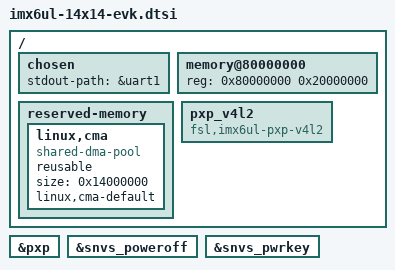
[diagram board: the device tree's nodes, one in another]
// SPDX-License-Identifier: GPL-2.0
//
// Copyright (C) 2015 Freescale Semiconductor, Inc.

#include <dt-bindings/media/video-interfaces.h>

/ {
	chosen {
		stdout-path = &uart1;
	};

	memory@80000000 {
		device_type = "memory";
		reg = <0x80000000 0x20000000>;
	};

	reserved-memory {
		#address-cells = <1>;
		#size-cells = <1>;
		ranges;

		linux,cma {
			compatible = "shared-dma-pool";
			reusable;
			size = <0x14000000>;
			linux,cma-default;
		};
	};

	pxp_v4l2 {
		compatible = "fsl,imx6ul-pxp-v4l2", "fsl,imx6sx-pxp-v4l2", "fsl,imx6sl-pxp-v4l2";
		status = "okay";
	};
};

&pxp {
	status = "okay";
};

&snvs_poweroff {
	status = "okay";
};

&snvs_pwrkey {
	status = "okay";
};

